# ATtiny841 register map
Vendor: Atmel
Registers are 8-bit, read-write, reset 0x0 unless marked. A register's access mark holds for its fields unless they carry their own. Offsets are from the block's base; [hi:lo] are bit positions; {n}, {i} and the like mark numbered series; <NAME> marks a mode.

## TOCPM — Timer/Counter Output Compare Pin
Base 0x00000066
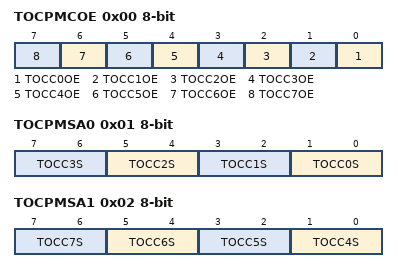
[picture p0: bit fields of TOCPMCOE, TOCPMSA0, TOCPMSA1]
0x00 TOCPMCOE — Timer Output Compare Pin Mux Channel Output Enable
  [n] TOCC{n}OE (n=0..7) — Timer Output Compare Channel {n} Output Enable
0x01 TOCPMSA0 — Timer Output Compare Pin Mux Selection 0
  [2n+1:2n] TOCC{n}S (n=0..3) — Timer Output Compare Channel {n} Selection Bits
0x02 TOCPMSA1 — Timer Output Compare Pin Mux Selection 1
  [2n-7:2n-8] TOCC{n}S (n=4..7) — Timer Output Compare Channel {n} Selection Bits

## TWI — Two Wire Serial Interface
Base 0x000000A0
0x00 TWSD ro — TWI Slave Data Register
  [7:0] TWSD — TWI slave data bit
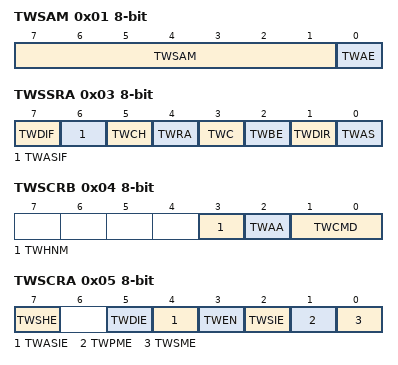
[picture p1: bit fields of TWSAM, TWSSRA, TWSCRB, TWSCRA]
0x01 TWSAM — TWI Slave Address Mask Register
  [7:1] TWSAM — TWI Address Mask Bits
  [0] TWAE — TWI Address Enable
0x02 TWSA ro — TWI Slave Address Register
0x03 TWSSRA — TWI Slave Status Register A
  [7] TWDIF — TWI Data Interrupt Flag.
  [6] TWASIF — TWI Address/Stop Interrupt Flag
  [5] TWCH — TWI Clock Hold
  [4] TWRA — TWI Receive Acknowledge
  [3] TWC — TWI Collision
  [2] TWBE — TWI Bus Error
  [1] TWDIR — TWI Read/Write Direction
  [0] TWAS — TWI Address or Stop
0x04 TWSCRB — TWI Slave Control Register B
  [3] TWHNM — TWI High Noise Mode
  [2] TWAA — TWI Acknowledge Action
    0=ACK_WRITE (Send ACK when TWCMD is written as 10 or 11); 1=ACK_READ (Send ACK when TWSD is read); 2=NACK_WRITE (Send NACK when TWCMD is written as 10 or 11); 3=NACK_READ (Send NACK when TWSD is read)
  [1:0] TWCMD — <TBD>
0x05 TWSCRA — TWI Slave Control Register A
  [7] TWSHE — TWI SDA Hold Time Enable
  [5] TWDIE — TWI Data Interrupt Enable
  [4] TWASIE — TWI Address/Stop Interrupt Enable
  [3] TWEN — Two-Wire Interface Enable
  [2] TWSIE — TWI Stop Interrupt Enable
  [1] TWPME — TWI Promiscuous Mode Enable
  [0] TWSME — TWI Smart Mode Enable

## USART0 — USART
Base 0x00000065
0x00 REMAP — Remap Port Pins
  [0] U0MAP — USART0 Pin Mapping
0x1B UDR0 — USART I/O Data Register
0x1C UBRR0 16-bit (reset mask 0xFF) — USART Baud Rate Register Bytes
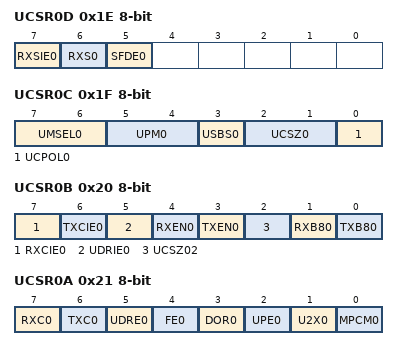
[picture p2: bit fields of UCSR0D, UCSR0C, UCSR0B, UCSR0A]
0x1E UCSR0D — USART Control and Status Register D
  [7] RXSIE0 — USART RX Start Interrupt Enable
  [6] RXS0 — USART RX Start Flag
  [5] SFDE0 — USART RX Start Frame Detection Enable
0x1F UCSR0C — USART Control and Status Register C
  [7:6] UMSEL0 — USART Mode Select
    0=USART_ASYNC (Asynchronous USART); 1=USART_SYNC (Synchronous USART); 3=SPI_MASTER (Master SPI (MSPIM))
  [5:4] UPM0 — Parity Mode Bits
    0=DISABLED; 2=PARITY_EVEN (Enabled, Even Parity); 3=PARITY_ODD (Enabled, Odd Parity)
  [3] USBS0 — Stop Bit Select
    0=STOP1 (1-bit); 1=STOP2 (2-bit)
  [2:1] UCSZ0 — Character Size
    {v}=CHR{v+5} (Character Size: {v+5} bit) (v=0..3)
  [0] UCPOL0 — Clock Polarity
    0=RISING_EDGE (Transmit on Rising XCKn Edge, Receive on Falling XCKn Edge); 1=FALLING_EDGE (Transmit on Falling XCKn Edge, Receive on Rising XCKn Edge)
0x20 UCSR0B — USART Control and Status Register B
  [7] RXCIE0 — RX Complete Interrupt Enable
  [6] TXCIE0 — TX Complete Interrupt Enable
  [5] UDRIE0 — USART Data register Empty Interrupt Enable
  [4] RXEN0 — Receiver Enable
  [3] TXEN0 — Transmitter Enable
  [2] UCSZ02 — Character Size
  [1] RXB80 ro — Receive Data Bit 8
  [0] TXB80 — Transmit Data Bit 8
0x21 UCSR0A — USART Control and Status Register A
  [7] RXC0 ro — USART Receive Complete
  [6] TXC0 — USART Transmit Complete
  [5] UDRE0 ro — USART Data Register Empty
  [4] FE0 ro — Framing Error
  [3] DOR0 ro — Data overRun
  [2] UPE0 ro — Parity Error
  [1] U2X0 — Double the USART transmission speed
  [0] MPCM0 — Multi-processor Communication Mode

## USART1 — USART
Base 0x00000090
0x00 UDR1 — USART I/O Data Register
0x01 UBRR1 16-bit (reset mask 0xFF) — USART Baud Rate Register Bytes
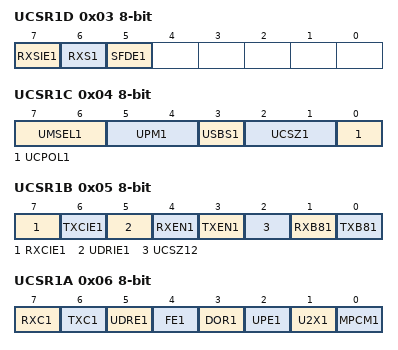
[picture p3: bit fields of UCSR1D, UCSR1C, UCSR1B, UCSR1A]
0x03 UCSR1D — USART Control and Status Register D
  [7] RXSIE1 — USART RX Start Interrupt Enable
  [6] RXS1 — USART RX Start Flag
  [5] SFDE1 — USART RX Start Frame Detection Enable
0x04 UCSR1C — USART Control and Status Register C
  [7:6] UMSEL1 — USART Mode Select
    0=USART_ASYNC (Asynchronous USART); 1=USART_SYNC (Synchronous USART); 3=SPI_MASTER (Master SPI (MSPIM))
  [5:4] UPM1 — Parity Mode Bits
    0=DISABLED; 2=PARITY_EVEN (Enabled, Even Parity); 3=PARITY_ODD (Enabled, Odd Parity)
  [3] USBS1 — Stop Bit Select
    0=STOP1 (1-bit); 1=STOP2 (2-bit)
  [2:1] UCSZ1 — Character Size
    {v}=CHR{v+5} (Character Size: {v+5} bit) (v=0..3)
  [0] UCPOL1 — Clock Polarity
    0=RISING_EDGE (Transmit on Rising XCKn Edge, Receive on Falling XCKn Edge); 1=FALLING_EDGE (Transmit on Falling XCKn Edge, Receive on Rising XCKn Edge)
0x05 UCSR1B — USART Control and Status Register B
  [7] RXCIE1 — RX Complete Interrupt Enable
  [6] TXCIE1 — TX Complete Interrupt Enable
  [5] UDRIE1 — USART Data register Empty Interrupt Enable
  [4] RXEN1 — Receiver Enable
  [3] TXEN1 — Transmitter Enable
  [2] UCSZ12 — Character Size
  [1] RXB81 ro — Receive Data Bit 8
  [0] TXB81 — Transmit Data Bit 8
0x06 UCSR1A — USART Control and Status Register A
  [7] RXC1 ro — USART Receive Complete
  [6] TXC1 — USART Transmit Complete
  [5] UDRE1 ro — USART Data Register Empty
  [4] FE1 ro — Framing Error
  [3] DOR1 ro — Data overRun
  [2] UPE1 ro — Parity Error
  [1] U2X1 — Double the USART transmission speed
  [0] MPCM1 — Multi-processor Communication Mode

## WDT — Watchdog Timer
Base 0x00000041
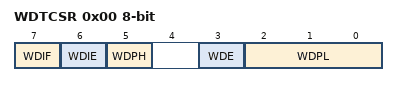
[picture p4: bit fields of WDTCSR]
0x00 WDTCSR — Watchdog Timer Control and Status Register
  [7] WDIF — Watchdog Timer Interrupt Flag
  [6] WDIE — Watchdog Timer Interrupt Enable
  [5] WDPH — Watchdog Timer Prescaler - High Bit
  [3] WDE — Watch Dog Enable
  [2:0] WDPL — Watchdog Timer Prescaler - Low Bits
    0=CYCLES_2K_512K (- 2048 cycles, ~16ms/512K (524288) cycles, ~4s if WDPH is set); 1=CYCLES_4K_1024K (- 4096 cycles, ~32ms/1024K (1048576) cycles, ~8s if WDPH is set); 2=CYCLES_8K (- 8192 cycles, ~64ms); 3=CYCLES_16K (- 16K (16384) cycles, ~0.125s); 4=CYCLES_32K (- 32K (32768) cycles, ~0.25s); 5=CYCLES_64K (- 64K (65536) cycles, ~0.5s); 6=CYCLES_128K (- 128K (131072) cycles, ~1s); 7=CYCLES_256K (- 256K (262144) cycles, ~2s)
